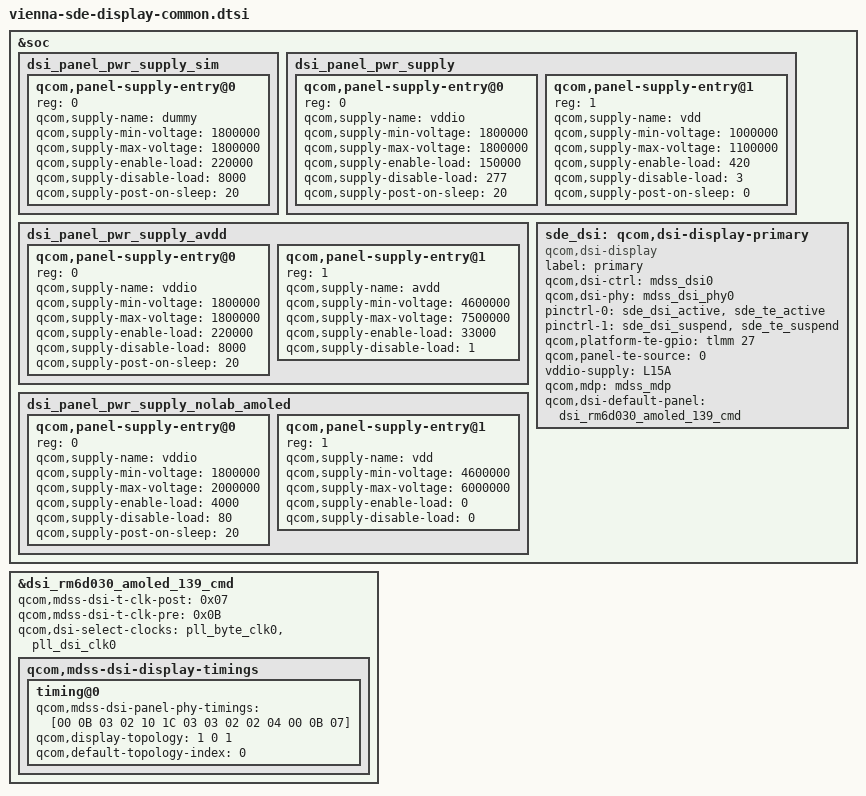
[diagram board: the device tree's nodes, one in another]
// SPDX-License-Identifier: BSD-3-Clause
/*
 * Copyright (c) 2025 Qualcomm Innovation Center, Inc. All rights reserved.
 */

#include "vienna-sde-display-pinctrl.dtsi"
#include "dsi-panel-rm6d030-amoled-139-cmd.dtsi"

&soc {
	dsi_panel_pwr_supply_sim: dsi_panel_pwr_supply_sim {
		#address-cells = <1>;
		#size-cells = <0>;

		qcom,panel-supply-entry@0 {
			reg = <0>;
			qcom,supply-name = "dummy";
			qcom,supply-min-voltage = <1800000>;
			qcom,supply-max-voltage = <1800000>;
			qcom,supply-enable-load = <220000>;
			qcom,supply-disable-load = <8000>;
			qcom,supply-post-on-sleep = <20>;
		};
	};

	dsi_panel_pwr_supply: dsi_panel_pwr_supply {
		#address-cells = <1>;
		#size-cells = <0>;

		qcom,panel-supply-entry@0 {
			reg = <0>;
			qcom,supply-name = "vddio";
			qcom,supply-min-voltage = <1800000>;
			qcom,supply-max-voltage = <1800000>;
			qcom,supply-enable-load = <150000>;
			qcom,supply-disable-load = <277>;
			qcom,supply-post-on-sleep = <20>;
		};

		qcom,panel-supply-entry@1 {
			reg = <1>;
			qcom,supply-name = "vdd";
			qcom,supply-min-voltage = <1000000>;
			qcom,supply-max-voltage = <1100000>;
			qcom,supply-enable-load = <420>;
			qcom,supply-disable-load = <3>;
			qcom,supply-post-on-sleep = <0>;
		};

	};

	dsi_panel_pwr_supply_avdd: dsi_panel_pwr_supply_avdd {
		#address-cells = <1>;
		#size-cells = <0>;

		qcom,panel-supply-entry@0 {
			reg = <0>;
			qcom,supply-name = "vddio";
			qcom,supply-min-voltage = <1800000>;
			qcom,supply-max-voltage = <1800000>;
			qcom,supply-enable-load = <220000>;
			qcom,supply-disable-load = <8000>;
			qcom,supply-post-on-sleep = <20>;
		};

		qcom,panel-supply-entry@1 {
			reg = <1>;
			qcom,supply-name = "avdd";
			qcom,supply-min-voltage = <4600000>;
			qcom,supply-max-voltage = <7500000>;
			qcom,supply-enable-load = <33000>;
			qcom,supply-disable-load = <1>;
		};
	};

	dsi_panel_pwr_supply_nolab_amoled: dsi_panel_pwr_supply_nolab_amoled {
		#address-cells = <1>;
		#size-cells = <0>;

		qcom,panel-supply-entry@0 {
			reg = <0>;
			qcom,supply-name = "vddio";
			qcom,supply-min-voltage = <1800000>;
			qcom,supply-max-voltage = <2000000>;
			qcom,supply-enable-load = <4000>;
			qcom,supply-disable-load = <80>;
			qcom,supply-post-on-sleep = <20>;
		};

		qcom,panel-supply-entry@1 {
			reg = <1>;
			qcom,supply-name = "vdd";
			qcom,supply-min-voltage = <4600000>;
			qcom,supply-max-voltage = <6000000>;
			qcom,supply-enable-load = <0>;
			qcom,supply-disable-load = <0>;
		};
	};

	sde_dsi: qcom,dsi-display-primary {
		compatible = "qcom,dsi-display";
		label = "primary";

		qcom,dsi-ctrl = <&mdss_dsi0>;
		qcom,dsi-phy = <&mdss_dsi_phy0>;

		pinctrl-names = "panel_active", "panel_suspend";
		pinctrl-0 = <&sde_dsi_active &sde_te_active>;
		pinctrl-1 = <&sde_dsi_suspend &sde_te_suspend>;

		qcom,platform-te-gpio = <&tlmm 27 0>;
		qcom,panel-te-source = <0>;

		vddio-supply = <&L15A>;

		qcom,mdp = <&mdss_mdp>;
		qcom,dsi-default-panel = <&dsi_rm6d030_amoled_139_cmd>;
	};
};

&dsi_rm6d030_amoled_139_cmd {
	qcom,mdss-dsi-t-clk-post = <0x07>;
	qcom,mdss-dsi-t-clk-pre = <0x0B>;
	qcom,dsi-select-clocks = "pll_byte_clk0", "pll_dsi_clk0";

	qcom,mdss-dsi-display-timings {
		timing@0 {
			qcom,mdss-dsi-panel-phy-timings = [00 0B 03 02 10 1C 03
				03 02 02 04 00 0B 07];
			qcom,display-topology = <1 0 1>;
			qcom,default-topology-index = <0>;
		};
	};
};
